# STM32WB55 register map
File version: 2.0
CPU: CM4 r0p1, little endian, MPU, FPU, 4 interrupt priority bits
Registers are 32-bit, read-write, reset 0x0 unless marked. A register's access mark holds for its fields unless they carry their own. Offsets are from the block's base; [hi:lo] are bit positions; {n}, {i} and the like mark numbered series; 'fields as' and 'values as' point back to an identical list.

## HSEM
Base 0x58001400
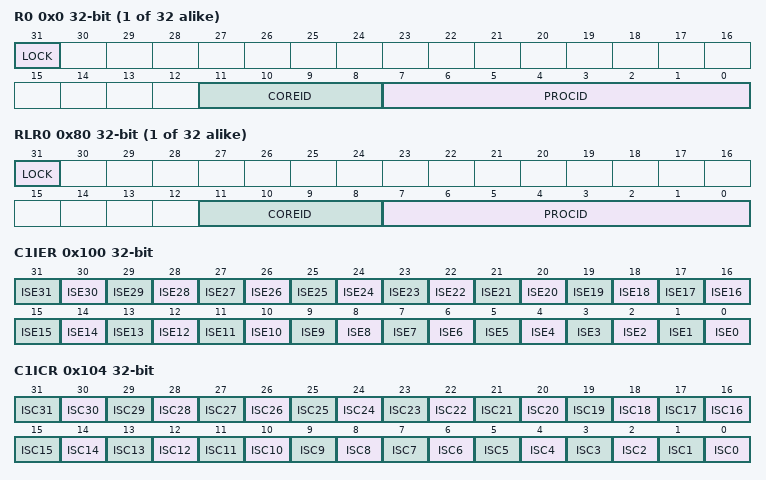
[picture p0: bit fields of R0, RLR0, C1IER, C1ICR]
{0x0+4i} R{i} (i=0..31) — HSEM register HSEM_R{i}
  [31] LOCK — lock indication
    on read: 0=Free (Semaphore is free); 1=Locked (Semaphore is locked) | on write: 0=Free semaphore; 1=TryLock (Try to lock semaphore)
  [11:8] COREID — Semaphore CoreID
  [7:0] PROCID — Semaphore ProcessID
{0x80+4i} RLR{i} (i=0..31) ro — Semaphore {i} read lock register
  [31] LOCK — lock indication
    0=Free (Semaphore is free); 1=Locked (Semaphore is locked)
  [11:8] COREID — Semaphore CoreID
  [7:0] PROCID — Semaphore ProcessID
0x100 C1IER — HSEM Interrupt enable register
  [n] ISE{n} (n=0..31) — Interrupt semaphore {n} enable bit
    0=Disabled (Interrupt generation disabled); 1=Enabled (Interrupt generation enabled)
0x104 C1ICR — HSEM Interrupt clear register
  [n] ISC{n} (n=0..31) — Interrupt semaphore {n} clear bit
    on read: 0=NoEffect (Always reads 0) | on write: 0=NoEffect (Interrupt semaphore x status ISFx and masked status MISFx not affected); 1=Clear (Interrupt semaphore x status ISFx and masked status MISFx cleared)
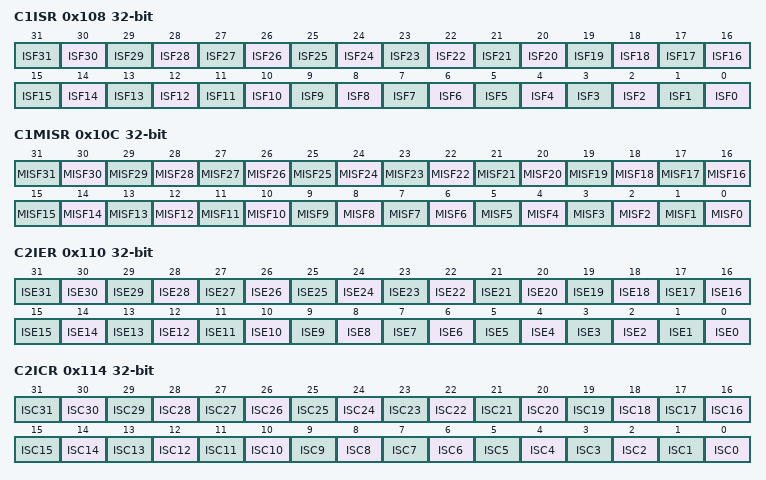
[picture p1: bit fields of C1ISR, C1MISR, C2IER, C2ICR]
0x108 C1ISR ro — HSEM Interrupt status register
  [n] ISF{n} (n=0..31) — Interrupt semaphore {n} status bit before enable (mask)
    0=NotPending (No interrupt pending); 1=Pending (Interrupt pending)
0x10C C1MISR ro — HSEM Masked interrupt status register
  [n] MISF{n} (n=0..31) — Masked interrupt semaphore {n} status bit after enable (mask)
    0=NotPending (No interrupt pending after masking); 1=Pending (Interrupt pending after masking)
0x110 C2IER — HSEM Interrupt enable register
  fields as C1IER
0x114 C2ICR — HSEM Interrupt clear register
  fields as C1ICR
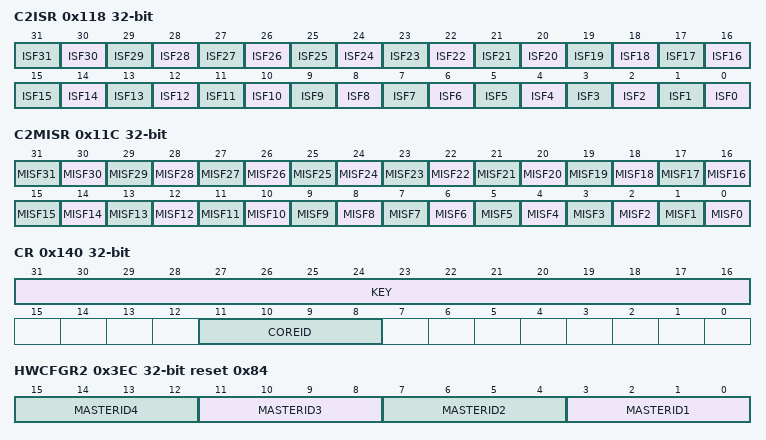
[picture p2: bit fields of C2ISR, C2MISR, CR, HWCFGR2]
0x118 C2ISR ro — HSEM Interrupt status register
  fields as C1ISR
0x11C C2MISR ro — HSEM Masked interrupt status register
  fields as C1MISR
0x140 CR — Semaphore Clear register
  [31:16] KEY — Semaphore clear Key
  [11:8] COREID — CoreID of semaphore to be cleared
0x144 KEYR — Interrupt clear register
  [31:16] KEY — Semaphore Clear Key
0x3EC HWCFGR2 ro reset 0x84 — Semaphore hardware configuration register 2
  [4n-1:4n-4] MASTERID{n} (n=1..4) — Hardware Configuration valid bus masters ID{n}
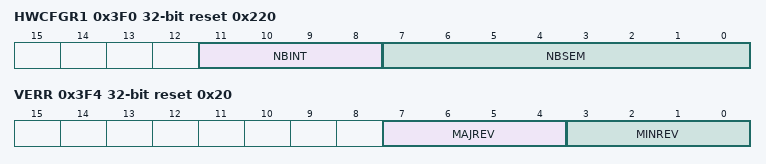
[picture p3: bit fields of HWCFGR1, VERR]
0x3F0 HWCFGR1 ro reset 0x220 — Semaphore hardware configuration register 1
  [11:8] NBINT — Hardware Configuration number of interrupts supported number of master IDs
  [7:0] NBSEM — Hardware Configuration number of semaphores
0x3F4 VERR ro reset 0x20 — HSEM version register
  [7:4] MAJREV — Major Revision
  [3:0] MINREV — Minor Revision
0x3F8 IPIDR ro reset 0x100072 — HSEM indentification register
  [31:0] ID — Identification Code
0x3FC SIDR ro reset 0xA3C5DD01 — HSEM size indentification register
  [31:0] SID — Size Identification Code

## ADC_Common — ADC common registers
Base 0x50040300
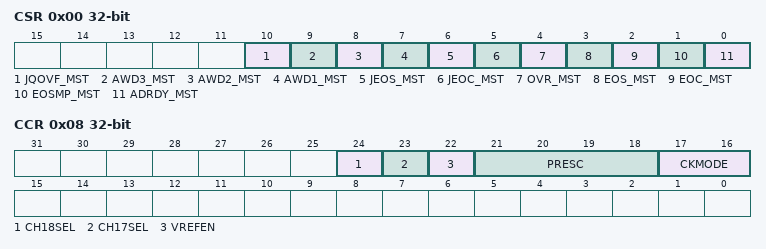
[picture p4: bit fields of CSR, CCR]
0x00 CSR ro — ADC common status register
  [10] JQOVF_MST — Injected Context Queue Overflow flag of the master ADC
  [9] AWD3_MST — Analog watchdog 3 flag of the master ADC
  [8] AWD2_MST — Analog watchdog 2 flag of the master ADC
  [7] AWD1_MST — Analog watchdog 1 flag of the master ADC
  [6] JEOS_MST — End of injected sequence flag of the master ADC
  [5] JEOC_MST — End of injected conversion flag of the master ADC
  [4] OVR_MST — Overrun flag of the master ADC
  [3] EOS_MST — End of regular sequence flag of the master ADC
  [2] EOC_MST — End of regular conversion flag of the master ADC
  [1] EOSMP_MST — End of Sampling phase flag of the master ADC
  [0] ADRDY_MST — master ADC ready
0x08 CCR — ADC common control register
  [24] CH18SEL — CH18 selection (Vbat)
  [23] CH17SEL — CH17 selection (temperature)
  [22] VREFEN — Vrefint enable
  [21:18] PRESC — ADC prescaler
  [17:16] CKMODE — ADC clock mode
